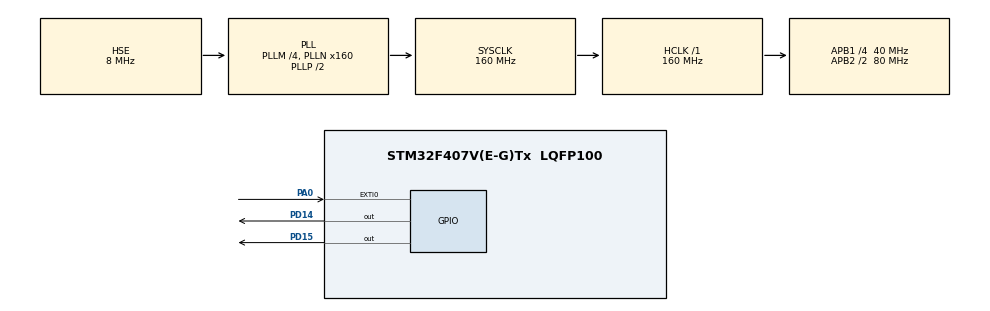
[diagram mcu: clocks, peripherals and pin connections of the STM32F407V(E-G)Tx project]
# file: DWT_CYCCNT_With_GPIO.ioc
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Mcu.Family=STM32F4
Mcu.Name=STM32F407V(E-G)Tx
Mcu.Package=LQFP100
NVIC.EXTI0_IRQn=true\:0\:1\:false\:false\:true\:true\:true
NVIC.PriorityGroup=NVIC_PRIORITYGROUP_0
PA0-WKUP.GPIO_ModeDefaultEXTI=GPIO_MODE_IT_RISING_FALLING
PA0-WKUP.Signal=GPXTI0
PA13.Mode=Serial_Wire
PA13.Signal=SYS_JTMS-SWDIO
PA14.Mode=Serial_Wire
PA14.Signal=SYS_JTCK-SWCLK
PD14.Signal=GPIO_Output
PD15.Signal=GPIO_Output
PH0-OSC_IN.Mode=HSE-External-Oscillator
PH0-OSC_IN.Signal=RCC_OSC_IN
PH1-OSC_OUT.Mode=HSE-External-Oscillator
PH1-OSC_OUT.Signal=RCC_OSC_OUT
ProjectManager.HeapSize=0x200
ProjectManager.StackSize=0x400
ProjectManager.TargetToolchain=STM32CubeIDE
RCC.48MHZClocksFreq_Value=45714285.71428572
RCC.AHBFreq_Value=160000000
RCC.APB1CLKDivider=RCC_HCLK_DIV4
RCC.APB1Freq_Value=40000000
RCC.APB1TimFreq_Value=80000000
RCC.APB2CLKDivider=RCC_HCLK_DIV2
RCC.APB2Freq_Value=80000000
RCC.APB2TimFreq_Value=160000000
RCC.CortexFreq_Value=160000000
RCC.HCLKFreq_Value=160000000
RCC.HSE_VALUE=8000000
RCC.HSI_VALUE=16000000
RCC.LSE_VALUE=32768
RCC.PLLM=4
RCC.PLLN=160
RCC.PLLQ=7
RCC.PLLSourceVirtual=RCC_PLLSOURCE_HSE
RCC.SYSCLKFreq_VALUE=160000000
RCC.SYSCLKSource=RCC_SYSCLKSOURCE_PLLCLK
RCC.VCOOutputFreq_Value=320000000
board=STM32F407G-DISC1

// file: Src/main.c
/* USER CODE BEGIN Header */
/**
 ******************************************************************************
 * @file           : main.c
 * @brief          : Main program body
 ******************************************************************************
 * @attention
 *
 * <h2><center>&copy; Copyright (c) 2019 STMicroelectronics.
 * All rights reserved.</center></h2>
 *
 * This software component is licensed by ST under Ultimate Liberty license
 * SLA0044, the "License"; You may not use this file except in compliance with
 * the License. You may obtain a copy of the License at:
 *                             www.st.com/SLA0044
 *
 ******************************************************************************
 */
/* USER CODE END Header */

#include "main.h"
#include "gpio.h"

/* USER CODE BEGIN PD */
#define DEMCR_TRCENA    0x01000000

/* Core Debug registers */
#define DEMCR           (*((volatile uint32_t *)0xE000EDFC))
#define DWT_CTRL        (*(volatile uint32_t *)0xe0001000)
#define CYCCNTENA       (1<<0)
#define DWT_CYCCNT      ((volatile uint32_t *)0xE0001004)
#define CPU_CYCLES      *DWT_CYCCNT

#define STOPWATCH_START { m_nStart = *((volatile unsigned int *)0xE0001004);}
#define STOPWATCH_STOP  { m_nStop = *((volatile unsigned int *)0xE0001004);}

/* USER CODE END PD */

/* USER CODE BEGIN PV */
uint32_t m_nStart;               //DEBUG Stopwatch start cycle counter value
uint32_t m_nStop;                //DEBUG Stopwatch stop cycle counter value
uint16_t tDelay = 300;
uint8_t make_A_High, make_A_BAR_High;
/* USER CODE END PV */

void SystemClock_Config(void);
/* USER CODE BEGIN PFP */
static inline void stopwatch_reset(void);
static inline uint32_t stopwatch_getticks();
static inline void stopwatch_delay(uint32_t ticks);
uint32_t CalcNanosecondsFromStopwatch(uint32_t nStart, uint32_t nStop);

/* USER CODE END PFP */

int main(void)
{

	/* MCU Configuration--------------------------------------------------------*/

	/* Reset of all peripherals, Initializes the Flash interface and the Systick. */
	HAL_Init();

	/* Configure the system clock */
	SystemClock_Config();

	/* Initialize all configured peripherals */
	MX_GPIO_Init();

	/* Infinite loop */
	/* USER CODE BEGIN WHILE */
	while (1)
	{
		int timeDiff = 0;
		stopwatch_reset();

		if(make_A_High == 1)
		{
			STOPWATCH_START;
			stopwatch_delay(tDelay);
			HAL_GPIO_WritePin(GPIOD, GPIO_PIN_14, GPIO_PIN_SET);
			make_A_High = 0;
			STOPWATCH_STOP;
			timeDiff = CalcNanosecondsFromStopwatch(m_nStart, m_nStop);
			make_A_High = 0;
		}

		if(make_A_BAR_High == 1)
		{
			STOPWATCH_START;
			stopwatch_delay(tDelay);
			HAL_GPIO_WritePin(GPIOD, GPIO_PIN_15, GPIO_PIN_SET);
			make_A_BAR_High = 0;
			STOPWATCH_STOP;
			timeDiff = CalcNanosecondsFromStopwatch(m_nStart, m_nStop);
			make_A_BAR_High = 0;

		}

		/* USER CODE END WHILE */

	}
}

void SystemClock_Config(void)
{
	RCC_OscInitTypeDef RCC_OscInitStruct = {0};
	RCC_ClkInitTypeDef RCC_ClkInitStruct = {0};

	/** Configure the main internal regulator output voltage
	 */
	__HAL_RCC_PWR_CLK_ENABLE();
	__HAL_PWR_VOLTAGESCALING_CONFIG(PWR_REGULATOR_VOLTAGE_SCALE1);
	/** Initializes the CPU, AHB and APB busses clocks
	 */
	RCC_OscInitStruct.OscillatorType = RCC_OSCILLATORTYPE_HSE;
	RCC_OscInitStruct.HSEState = RCC_HSE_ON;
	RCC_OscInitStruct.PLL.PLLState = RCC_PLL_ON;
	RCC_OscInitStruct.PLL.PLLSource = RCC_PLLSOURCE_HSE;
	RCC_OscInitStruct.PLL.PLLM = 4;
	RCC_OscInitStruct.PLL.PLLN = 160;
	RCC_OscInitStruct.PLL.PLLP = RCC_PLLP_DIV2;
	RCC_OscInitStruct.PLL.PLLQ = 7;
	if (HAL_RCC_OscConfig(&RCC_OscInitStruct) != HAL_OK)
	{
		Error_Handler();
	}
	/** Initializes the CPU, AHB and APB busses clocks
	 */
	RCC_ClkInitStruct.ClockType = RCC_CLOCKTYPE_HCLK|RCC_CLOCKTYPE_SYSCLK
			|RCC_CLOCKTYPE_PCLK1|RCC_CLOCKTYPE_PCLK2;
	RCC_ClkInitStruct.SYSCLKSource = RCC_SYSCLKSOURCE_PLLCLK;
	RCC_ClkInitStruct.AHBCLKDivider = RCC_SYSCLK_DIV1;
	RCC_ClkInitStruct.APB1CLKDivider = RCC_HCLK_DIV4;
	RCC_ClkInitStruct.APB2CLKDivider = RCC_HCLK_DIV2;

	if (HAL_RCC_ClockConfig(&RCC_ClkInitStruct, FLASH_LATENCY_5) != HAL_OK)
	{
		Error_Handler();
	}
}

/* USER CODE BEGIN 4 */
static inline void stopwatch_reset(void)
{
	/* Enable DWT */
	DEMCR |= DEMCR_TRCENA;
	*DWT_CYCCNT = 0;
	/* Enable CPU cycle counter */
	DWT_CTRL |= CYCCNTENA;
}

static inline uint32_t stopwatch_getticks()
{
	return CPU_CYCLES;
}

static inline void stopwatch_delay(uint32_t ticks)
{
	uint32_t end_ticks = ticks + stopwatch_getticks();
	while(1)
	{
		if (stopwatch_getticks() >= end_ticks)
			break;
	}
}

uint32_t CalcNanosecondsFromStopwatch(uint32_t nStart, uint32_t nStop)
{
	uint32_t nDiffTicks;
	uint32_t nClkTicksPerMicrosec;

	nDiffTicks = nStop - nStart;
	nDiffTicks *= 1000;                               // Scale diff by 1000.
	nClkTicksPerMicrosec = SystemCoreClock / 1000000; // Convert (clkTicks/sec) to (clkTicks/microsec), SystemCoreClock = 168000000

	return nDiffTicks / nClkTicksPerMicrosec;         // nanosec = (ticks * 1000) / (clkTicks/microsec)
}

/* USER CODE END 4 */

void Error_Handler(void)
{
}

/************************ (C) COPYRIGHT STMicroelectronics *****END OF FILE****/
